# M311 register map
File version: 2.0.2.1
Registers are 32-bit, read-write, reset 0x0 unless marked. A register's access mark holds for its fields unless they carry their own. Offsets are from the block's base; [hi:lo] are bit positions; {n}, {i} and the like mark numbered series.

## T16A — 16-bit TimerA (T16A)
Base 0x4008D000
0x00 EN — Enable Register
  [1] HALT
0x04 RUN
  [0] RUN
0x08 CR reset 0x30 — Control Register
  [0] CLK
0x0C RG — Timer Register
  [15:0] RG
0x10 CP ro — Capture Register
  [15:0] CP

## INT — Interrupt Controller (INT)
Base 0x400B8000
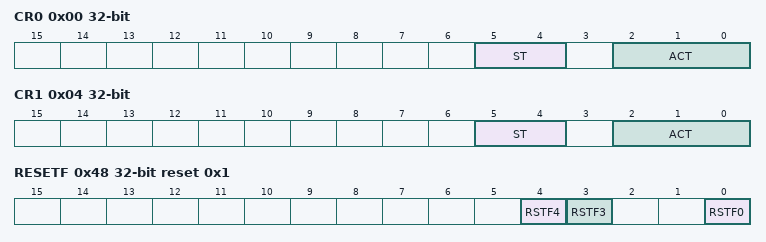
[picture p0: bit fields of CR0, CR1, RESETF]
0x00 CR0 — Control Register 0
  [5:4] ST ro, [2:0] ACT
0x04 CR1 — Control Register 1
  [5:4] ST ro, [2:0] ACT
0x44 CLR wo — Interrupt Request Clear Register
  [0] CLR
0x48 RESETF reset 0x1 — Reset Flag Register
  [4] RSTF4, [3] RSTF3, [0] RSTF0

## PA — Port A (PA)
Base 0x400C0000
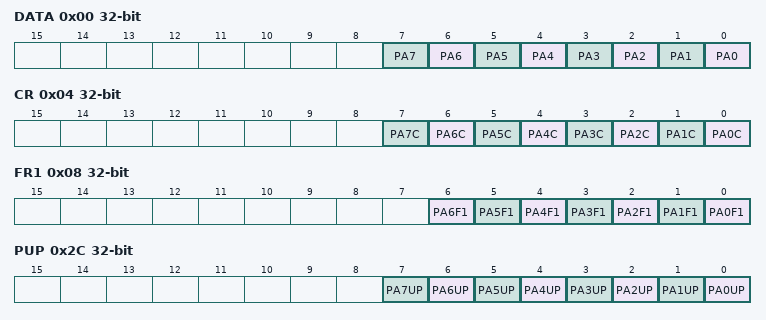
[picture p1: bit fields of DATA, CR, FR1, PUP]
0x00 DATA
  [n] PA{n} (n=0..7)
0x04 CR — Output Control Register
  [n] PA{n}C (n=0..7)
0x08 FR1 — Function Register 1
  [n] PA{n}F1 (n=0..6)
0x2C PUP — Pull-up Control Register
  [n] PA{n}UP (n=0..7)
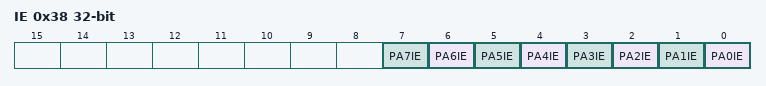
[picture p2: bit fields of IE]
0x38 IE — Input Control Register
  [n] PA{n}IE (n=0..7)

## PB — Port B (PB)
Base 0x400C0100
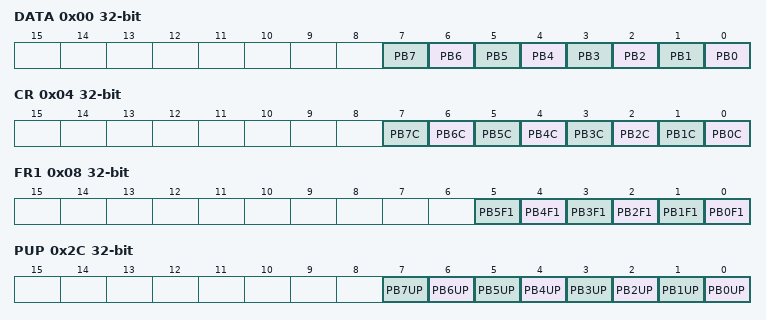
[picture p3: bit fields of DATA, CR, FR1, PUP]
0x00 DATA
  [n] PB{n} (n=0..7)
0x04 CR — Output Control Register
  [n] PB{n}C (n=0..7)
0x08 FR1 — Function Register 1
  [n] PB{n}F1 (n=0..5)
0x2C PUP — Pull-up Control Register
  [n] PB{n}UP (n=0..7)
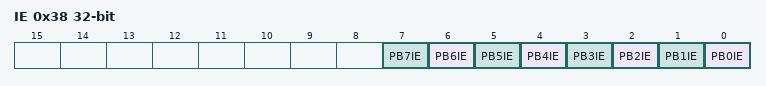
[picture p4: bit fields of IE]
0x38 IE — Input Control Register
  [n] PB{n}IE (n=0..7)

## PC — Port C (PC)
Base 0x400C0200
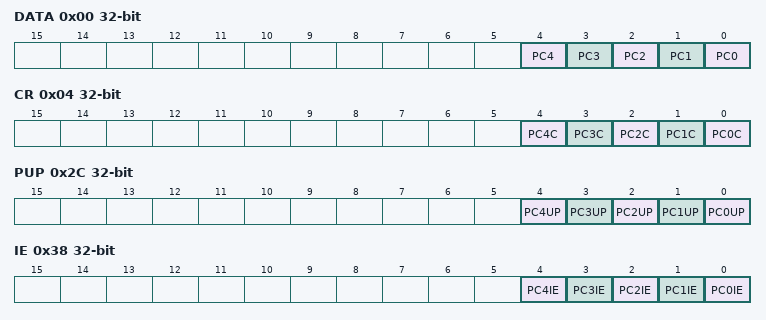
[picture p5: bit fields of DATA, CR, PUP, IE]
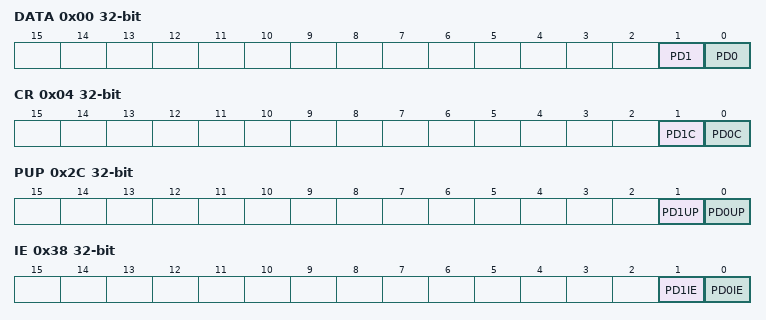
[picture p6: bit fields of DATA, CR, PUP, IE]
0x00 DATA
  [n] PC{n} (n=0..4)
0x04 CR — Output Control Register
  [n] PC{n}C (n=0..4)
0x08 FR1 — Function Register 1
  [2] PC2F1
0x2C PUP — Pull-up Control Register
  [n] PC{n}UP (n=0..4)
0x30 PDN — Pull-down Control Register
  [3] PC3DN
0x38 IE — Input Control Register
  [n] PC{n}IE (n=0..4)

## PD — Port D (PD)
Base 0x400C0300
0x00 DATA
  [1] PD1, [0] PD0
0x04 CR — Output Control Register
  [1] PD1C, [0] PD0C
0x2C PUP — Pull-up Control Register
  [1] PD1UP, [0] PD0UP
0x38 IE — Input Control Register
  [1] PD1IE, [0] PD0IE

## TB0 — 16-bit Timer_Event Counter (TB)
Base 0x400C4000
Same registers: TB1 0x400C4100, TB2 0x400C4200, TB3 0x400C4300
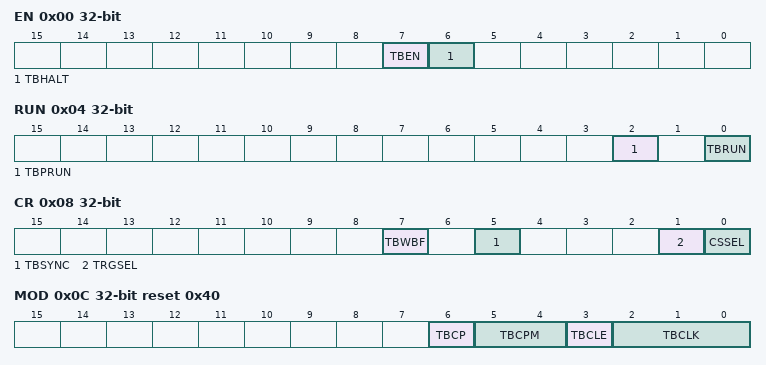
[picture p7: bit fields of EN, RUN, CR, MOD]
0x00 EN — Enable Register
  [7] TBEN, [6] TBHALT
0x04 RUN
  [2] TBPRUN, [0] TBRUN
0x08 CR — Control Register
  [7] TBWBF, [5] TBSYNC, [1] TRGSEL, [0] CSSEL
0x0C MOD reset 0x40 — Mode Register
  [6] TBCP wo, [5:4] TBCPM, [3] TBCLE, [2:0] TBCLK
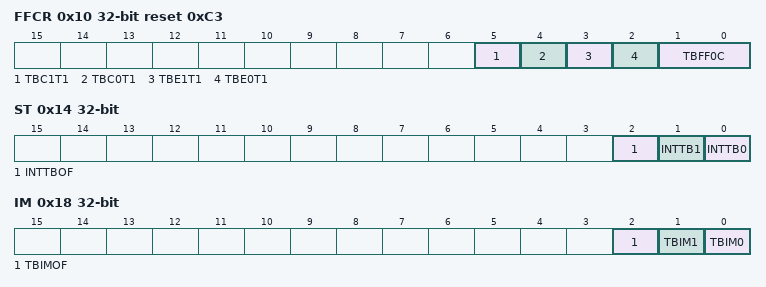
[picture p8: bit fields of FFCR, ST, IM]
0x10 FFCR reset 0xC3 — Flip-Flop Control Register
  [5] TBC1T1, [4] TBC0T1, [3] TBE1T1, [2] TBE0T1, [1:0] TBFF0C
0x14 ST ro — Status Register
  [2] INTTBOF, [1] INTTB1, [0] INTTB0
0x18 IM — Interrupt Mask Register
  [2] TBIMOF, [1] TBIM1, [0] TBIM0
0x1C UC ro — Up-counter Capture Register
  [15:0] TBUC
0x20 RG0 — RG0 Timer Register
  [15:0] TBRG0
0x24 RG1 — RG1 Timer Register
  [15:0] TBRG1
0x28 CP0 ro (reset mask 0xFFFF0000) — CP0 Capture Register
  [15:0] TBCP0
0x2C CP1 ro (reset mask 0xFFFF0000) — CP1 Capture Register
  [15:0] TBCP1

## SC — SIO_UART (SC)
Base 0x400E1000
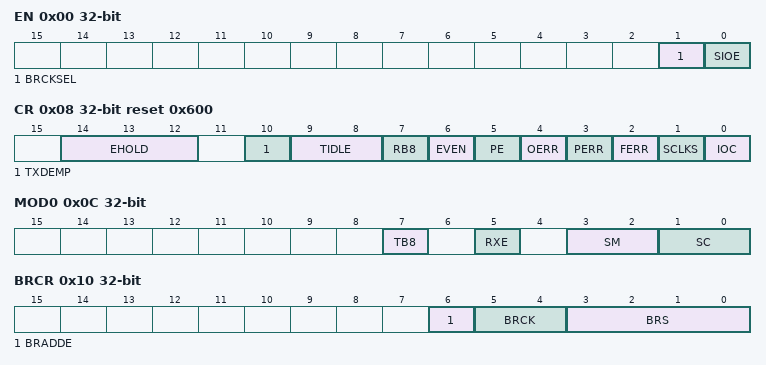
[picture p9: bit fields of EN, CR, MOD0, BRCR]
0x00 EN — Enable Register
  [1] BRCKSEL, [0] SIOE
0x04 BUF — Buffer Register
  [7:0] TB_RB
0x08 CR reset 0x600 — Control Register
  [14:12] EHOLD, [10] TXDEMP, [9:8] TIDLE, [7] RB8 ro, [6] EVEN, [5] PE, [4] OERR ro, [3] PERR ro, [2] FERR ro, [1] SCLKS, [0] IOC
0x0C MOD0 — Mode Control Register 0
  [7] TB8, [5] RXE, [3:2] SM, [1:0] SC
0x10 BRCR — Baud Rate Generator Control Register
  [6] BRADDE, [5:4] BRCK, [3:0] BRS
0x14 BRADD — Baud Rate Generator Control Register 2
  [3:0] BRK
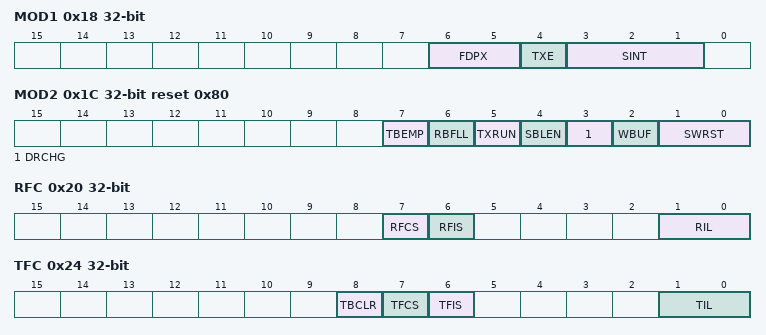
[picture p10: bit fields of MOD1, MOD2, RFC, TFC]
0x18 MOD1 — Mode Control Register 1
  [6:5] FDPX, [4] TXE, [3:1] SINT
0x1C MOD2 reset 0x80 — Mode Control Register 2
  [7] TBEMP ro, [6] RBFLL ro, [5] TXRUN ro, [4] SBLEN, [3] DRCHG, [2] WBUF, [1:0] SWRST
0x20 RFC — RX FIFO Configuration Register
  [7] RFCS wo, [6] RFIS, [1:0] RIL
0x24 TFC — TX FIFO Configuration Register
  [8] TBCLR wo, [7] TFCS wo, [6] TFIS, [1:0] TIL
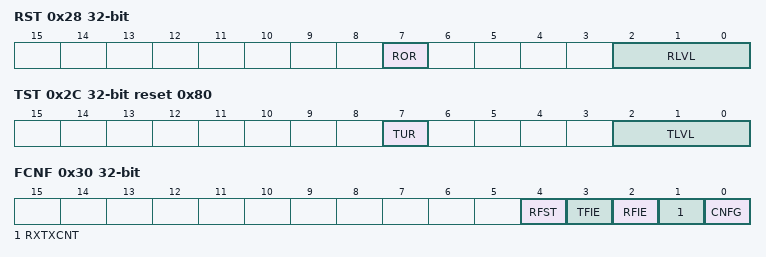
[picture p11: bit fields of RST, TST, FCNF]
0x28 RST ro — RX FIFO Status Register
  [7] ROR, [2:0] RLVL
0x2C TST ro reset 0x80 — TX FIFO Status Register
  [7] TUR, [2:0] TLVL
0x30 FCNF — FIFO Configuration Register
  [4] RFST, [3] TFIE, [2] RFIE, [1] RXTXCNT, [0] CNFG

## WD — Watchdog Timer (WD)
Base 0x400F2000
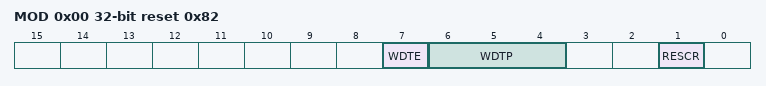
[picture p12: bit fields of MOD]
0x00 MOD reset 0x82 — Mode Register
  [7] WDTE, [6:4] WDTP, [1] RESCR
0x04 CR wo — Control Register
  [7:0] WDCR
0x08 FLG ro — Flag Register
  [0] FLG

## CG — Clock Control (CG)
Base 0x400F3000
0x00 PROTECT reset 0xC1
  [7:0] CGPROTECT
0x04 OSCSEL — High-speed oscillation select Register
  [1:0] OSCSEL
0x08 OSCSTF ro — High-speed oscillation status Register
  [1:0] OSCF
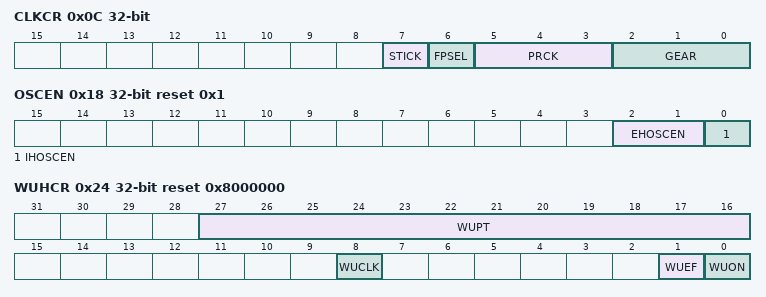
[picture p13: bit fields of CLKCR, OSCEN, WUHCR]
0x0C CLKCR — Clock Control Register
  [7] STICK, [6] FPSEL, [5:3] PRCK, [2:0] GEAR
0x18 OSCEN reset 0x1 — Oscillation enable Register
  [2:1] EHOSCEN, [0] IHOSCEN
0x24 WUHCR reset 0x8000000 — High-speed oscillation warm-up Control Register
  [27:16] WUPT, [8] WUCLK, [1] WUEF ro, [0] WUON wo
